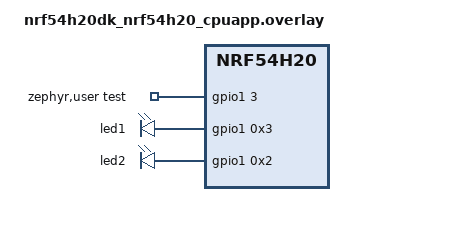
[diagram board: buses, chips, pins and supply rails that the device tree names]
/*
 * Copyright (c) 2024 Nordic Semiconductor
 *
 * SPDX-License-Identifier: Apache-2.0
 */

#include <zephyr/dt-bindings/gpio/gpio.h>

/*
 * P1.03 looped back to P1.02
 */

/ {
	aliases {
		test-comp = &comp;
	};

	zephyr,user {
		test-gpios = <&gpio1 3 GPIO_ACTIVE_HIGH>;
	};
};

&gpio1 {
	status = "okay";
};

/* Temporary workaround to reserve P1.03 for cpuapp */
&led1 {
	gpios = <&gpio1 0x3 0x0>;
};

/* Temporary workaround to reserve P1.02 for cpuapp */
&led2 {
	gpios = <&gpio1 0x2 0x0>;
};
